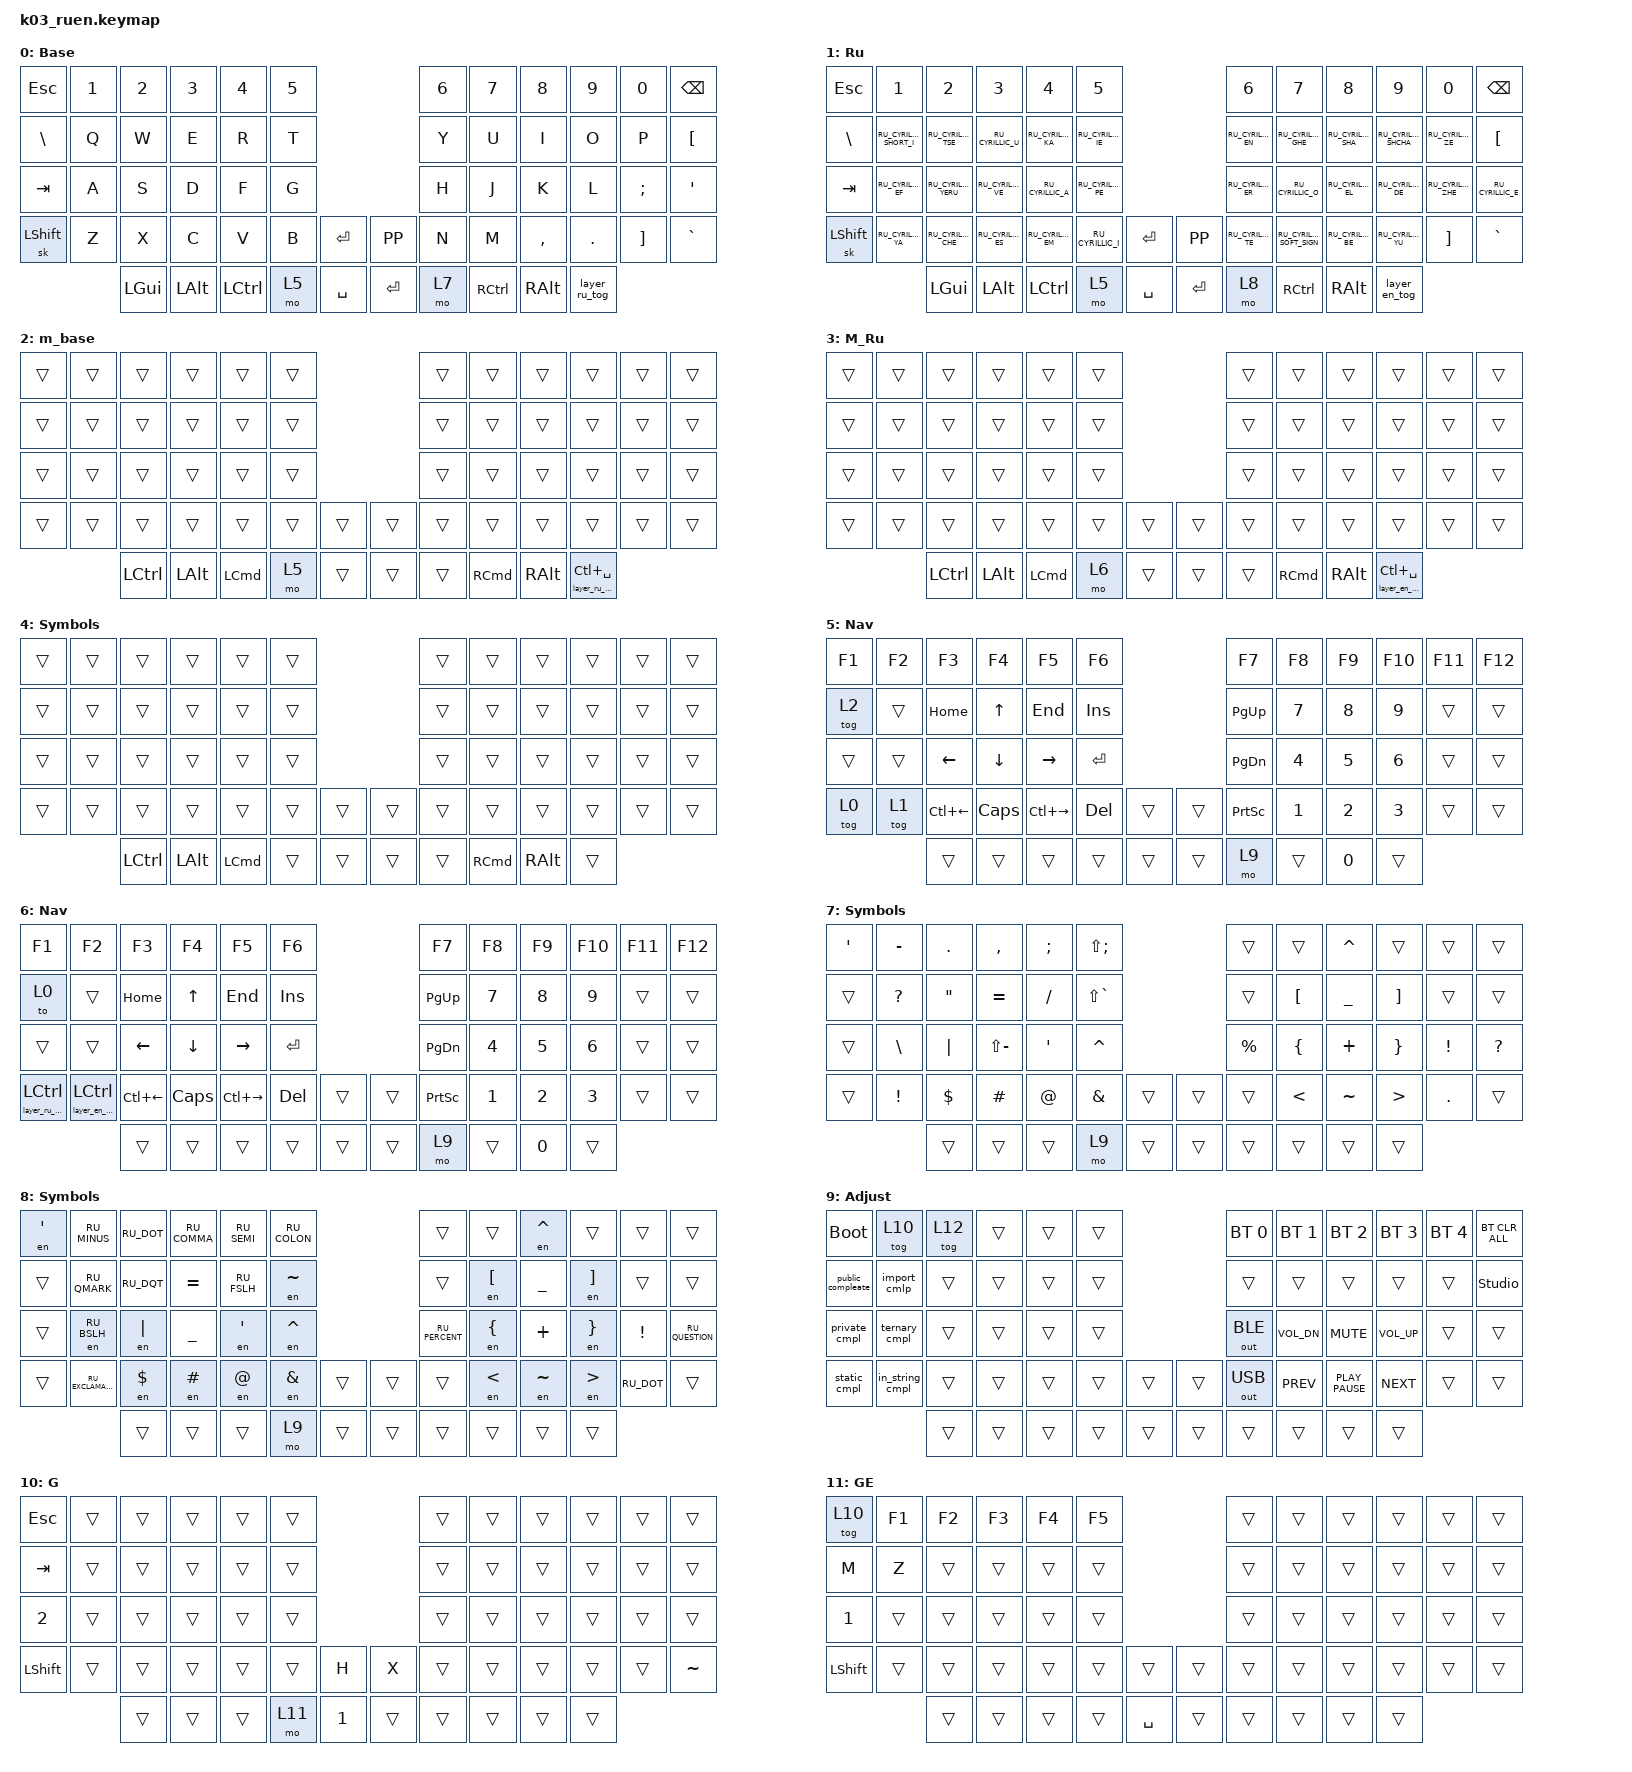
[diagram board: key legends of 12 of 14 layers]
#include "keys_ru.h"
#include <behaviors.dtsi>
#include <dt-bindings/zmk/bt.h>
#include <dt-bindings/zmk/keys.h>
#include <dt-bindings/zmk/outputs.h>

/ {
    behaviors {
        enc_vol: enc_vol {
            compatible = "zmk,behavior-sensor-rotate";
            label = "ENC_VOL";
            #sensor-binding-cells = <0>;
            bindings = <&kp C_VOL_UP>, <&kp C_VOL_DN>;

            tap-ms = <0>;
        };

        enc_up_down: enc_up_down {
            compatible = "zmk,behavior-sensor-rotate";
            label = "ENC_UP_DOWN";
            #sensor-binding-cells = <0>;
            bindings = <&kp UP>, <&kp DOWN>;

            tap-ms = <0>;
        };

        enc_left_right: enc_left_right {
            compatible = "zmk,behavior-sensor-rotate";
            label = "ENC_LEFT_RIGHT";
            #sensor-binding-cells = <0>;
            bindings = <&kp RIGHT>, <&kp LEFT>;

            tap-ms = <0>;
        };

        switch_window: switch_window {
            compatible = "zmk,behavior-sensor-rotate";
            label = "SWITCH_WINDOW";
            #sensor-binding-cells = <0>;
            bindings = <&kp LA(TAB)>, <&kp LS(LA(TAB))>;
        };

        switch_tab: switch_tab {
            compatible = "zmk,behavior-sensor-rotate";
            label = "SWITCH_TAB";
            #sensor-binding-cells = <0>;
            bindings = <&kp LC(TAB)>, <&kp LC(LS(TAB))>;
        };

        game_g_h: game_g_h {
            compatible = "zmk,behavior-sensor-rotate";
            label = "GAME_G_H";
            #sensor-binding-cells = <0>;
            bindings = <&kp G>, <&kp H>;
        };

        game_e_x: game_e_x {
            compatible = "zmk,behavior-sensor-rotate";
            label = "GAME_E_X";
            #sensor-binding-cells = <0>;
            bindings = <&kp E>, <&kp X>;
        };

        mac_switch_window: mac_switch_window {
            compatible = "zmk,behavior-sensor-rotate";
            label = "MAC_SWITCH_WINDOW";
            #sensor-binding-cells = <0>;
            bindings = <&kp LG(TAB)>, <&kp LG(LS(TAB))>;
        };

        enc_tabbing: enc_tabbing {
            compatible = "zmk,behavior-sensor-rotate";
            label = "ENC_TABBING";
            #sensor-binding-cells = <0>;
            bindings = <&kp TAB>, <&kp LS(TAB)>;
        };

        shift_tap_danse: shift_tap_danse {
            compatible = "zmk,behavior-tap-dance";
            label = "SHIFT_TAP_DANSE";
            #binding-cells = <0>;
            bindings = <&sk LSHFT>, <&kp LEFT_SHIFT>;
        };

        rotate_with_param: rotate_with_param {
            compatible = "zmk,behavior-sensor-rotate-var";
            label = "ROTATE_WITH_PARAM";
            #sensor-binding-cells = <2>;
            bindings = <&delayed_macro>, <&delayed_macro>;
        };
    };

    combos {
        compatible = "zmk,combos";

        cmben {
            bindings = <&layer_en>;
            key-positions = <12 13>;
            layers = <1>;
        };

        cmbru {
            bindings = <&layer_ru>;
            key-positions = <12 13>;
            layers = <0>;
        };

        dot_slash {
            bindings = <&dot_slash>;
            key-positions = <2 3>;
            layers = <1>;
        };

        dot_slash_en {
            bindings = <&dot_slash_en>;
            key-positions = <2 3>;
            layers = <0>;
        };
    };

    macros {
        to_ru: to_ru {
            compatible = "zmk,behavior-macro";
            #binding-cells = <0>;
            bindings = <&kp LS(LC(N2))>;
            label = "TO_RU";
            wait-ms = <0>;
            tap-ms = <30>;
        };

        to_en: to_en {
            compatible = "zmk,behavior-macro";
            #binding-cells = <0>;
            bindings = <&kp LS(LC(N1))>;
            label = "TO_EN";
            wait-ms = <0>;
            tap-ms = <30>;
        };

        layer_en: layer_en {
            compatible = "zmk,behavior-macro";
            #binding-cells = <0>;
            bindings = <&to 0 &to_en>;
            label = "LAYER_EN";
            wait-ms = <0>;
            tap-ms = <30>;
        };

        layer_ru: layer_ru {
            compatible = "zmk,behavior-macro";
            #binding-cells = <0>;
            bindings = <&to 1 &to_ru>;
            label = "LAYER_RU";
            tap-ms = <30>;
            wait-ms = <0>;
        };

        en: en {
            compatible = "zmk,behavior-macro-one-param";
            #binding-cells = <1>;
            bindings =
                <&to_en>,
                <&macro_press>,
                <&macro_param_1to1 &kp MACRO_PLACEHOLDER>,
                <&macro_pause_for_release>,
                <&macro_release>,
                <&macro_param_1to1 &kp MACRO_PLACEHOLDER>,
                <&macro_tap>,
                <&to_ru>;

            label = "EN";
            wait-ms = <0>;
            tap-ms = <30>;
        };

        change_lang: change_lang {
            compatible = "zmk,behavior-macro";
            #binding-cells = <0>;
            bindings = <&kp LG(SPACE)>;
            label = "CHANGE_LANG";
        };

        dot_slash: dot_slash {
            compatible = "zmk,behavior-macro";
            #binding-cells = <0>;
            bindings = <&kp RU_DOT &kp RU_SLASH>;
            label = "DOT_SLASH";
        };

        public_compleate: public_compleate {
            compatible = "zmk,behavior-macro";
            #binding-cells = <0>;
            bindings = <&kp P &kp U &kp B &kp L &kp I &kp C &kp SPACE>;
            label = "PUBLIC_COMPLEATE";
        };

        private_cmpl: private_cmpl {
            compatible = "zmk,behavior-macro";
            #binding-cells = <0>;
            bindings = <&kp P &kp R &kp I &kp V &kp A &kp T &kp E &kp SPACE>;
            label = "PRIVATE_CMPL";
        };

        static_cmpl: static_cmpl {
            compatible = "zmk,behavior-macro";
            #binding-cells = <0>;
            bindings = <&kp S &kp T &kp A &kp T &kp I &kp C &kp SPACE>;
            label = "STATIC_CMPL";
        };

        import_cmlp: import_cmlp {
            compatible = "zmk,behavior-macro";
            #binding-cells = <0>;
            bindings = <&kp I &kp M &kp P &kp O &kp R &kp T &kp SPACE>;
            label = "IMPORT_CMLP";
        };

        ternary_cmpl: ternary_cmpl {
            compatible = "zmk,behavior-macro";
            #binding-cells = <0>;
            bindings = <&kp QMARK &kp SPACE &kp SPACE &kp COLON &kp SPACE &kp LEFT &kp LEFT &kp LEFT>;
            label = "TERNARY_CMPL";
        };

        in_string_cmpl: in_string_cmpl {
            compatible = "zmk,behavior-macro";
            #binding-cells = <0>;
            bindings = <&kp BSLH &kp LPAR &kp RPAR &kp LEFT>;
            label = "IN_STRING_CMPL";
        };

        change_lang_mac: change_lang_mac {
            compatible = "zmk,behavior-macro";
            #binding-cells = <0>;
            bindings = <&kp LC(SPACE)>;
            label = "CHANGE_LANG_MAC";
        };

        layer_en_tog: layer_en_tog {
            compatible = "zmk,behavior-macro";
            #binding-cells = <0>;
            bindings = <&to 0 &change_lang>;
            label = "LAYER_EN_TOG";
            wait-ms = <0>;
            tap-ms = <30>;
        };

        layer_ru_tog: layer_ru_tog {
            compatible = "zmk,behavior-macro";
            #binding-cells = <0>;
            bindings = <&to 1 &change_lang>;
            label = "LAYER_RU_TOG";
            wait-ms = <0>;
            tap-ms = <30>;
        };

        layer_ru_mac_tog: layer_ru_mac_tog {
            compatible = "zmk,behavior-macro-one-param";
            #binding-cells = <1>;
            bindings = <&to 1 &tog 3 &macro_param_1to1 &kp MACRO_PLACEHOLDER>;
            label = "LAYER_RU_MAC_TOG";
        };

        layer_en_mac_tog: layer_en_mac_tog {
            compatible = "zmk,behavior-macro-one-param";
            #binding-cells = <1>;
            bindings = <&to 0 &tog 2 &macro_param_1to1 &kp MACRO_PLACEHOLDER>;
            label = "LAYER_EN_MAC_TOG";
        };

        dot_slash_en: dot_slash_en {
            compatible = "zmk,behavior-macro";
            #binding-cells = <0>;
            bindings = <&to_ru &dot_slash &to_en>;
            label = "DOT_SLASH_EN";
        };

        delayed_macro: delayed_macro {
            compatible = "zmk,behavior-macro-one-param";
            #binding-cells = <1>;
            bindings =
                <&macro_pause_for_release>,
                <&macro_tap>,
                <&macro_tap_time 1>,
                <&macro_param_1to1 &kp MACRO_PLACEHOLDER>;

            label = "DELAYED_MACRO";
        };
    };

    keymap {
        compatible = "zmk,keymap";

        en {
            bindings = <
&kp ESC         &kp N1  &kp N2    &kp N3    &kp N4     &kp N5                          &kp N6  &kp N7     &kp N8     &kp N9         &kp N0             &kp BSPC
&kp BACKSLASH   &kp Q   &kp W     &kp E     &kp R      &kp T                           &kp Y   &kp U      &kp I      &kp O          &kp P              &kp LEFT_BRACKET
&kp TAB         &kp A   &kp S     &kp D     &kp F      &kp G                           &kp H   &kp J      &kp K      &kp L          &kp SEMI           &kp SQT
&sk LEFT_SHIFT  &kp Z   &kp X     &kp C     &kp V      &kp B   &kp ENTER    &kp K_PP   &kp N   &kp M      &kp COMMA  &kp DOT        &kp RIGHT_BRACKET  &kp GRAVE
                        &kp LGUI  &kp LALT  &kp LCTRL  &mo 5   &kp SPACE    &kp ENTER  &mo 7   &kp RCTRL  &kp RALT   &layer_ru_tog
            >;

            display-name = "Base";
            sensor-bindings =
                <&rotate_with_param UP DOWN>,
                <&rotate_with_param RIGHT_ARROW LEFT_ARROW>;
        };

        ru {
            display-name = "Ru";
            bindings = <
&kp ESC        &kp N1                   &kp N2                &kp N3              &kp N4              &kp N5                                      &kp N6              &kp N7                     &kp N8               &kp N9                 &kp N0               &kp BSPC
&kp BACKSLASH  &kp RU_CYRILLIC_SHORT_I  &kp RU_CYRILLIC_TSE   &kp RU_CYRILLIC_U   &kp RU_CYRILLIC_KA  &kp RU_CYRILLIC_IE                          &kp RU_CYRILLIC_EN  &kp RU_CYRILLIC_GHE        &kp RU_CYRILLIC_SHA  &kp RU_CYRILLIC_SHCHA  &kp RU_CYRILLIC_ZE   &kp LEFT_BRACKET
&kp TAB        &kp RU_CYRILLIC_EF       &kp RU_CYRILLIC_YERU  &kp RU_CYRILLIC_VE  &kp RU_CYRILLIC_A   &kp RU_CYRILLIC_PE                          &kp RU_CYRILLIC_ER  &kp RU_CYRILLIC_O          &kp RU_CYRILLIC_EL   &kp RU_CYRILLIC_DE     &kp RU_CYRILLIC_ZHE  &kp RU_CYRILLIC_E
&sk LSHFT      &kp RU_CYRILLIC_YA       &kp RU_CYRILLIC_CHE   &kp RU_CYRILLIC_ES  &kp RU_CYRILLIC_EM  &kp RU_CYRILLIC_I   &kp ENTER    &kp K_PP   &kp RU_CYRILLIC_TE  &kp RU_CYRILLIC_SOFT_SIGN  &kp RU_CYRILLIC_BE   &kp RU_CYRILLIC_YU     &kp RIGHT_BRACKET    &kp GRAVE
                                        &kp LGUI              &kp LALT            &kp LCTRL           &mo 5               &kp SPACE    &kp ENTER  &mo 8               &kp RCTRL                  &kp RALT             &layer_en_tog
            >;

            sensor-bindings =
                <&rotate_with_param UP DOWN>,
                <&rotate_with_param RIGHT_ARROW LEFT_ARROW>;
        };

        mac_en {
            bindings = <
&trans  &trans  &trans     &trans        &trans    &trans                    &trans  &trans    &trans    &trans                       &trans  &trans
&trans  &trans  &trans     &trans        &trans    &trans                    &trans  &trans    &trans    &trans                       &trans  &trans
&trans  &trans  &trans     &trans        &trans    &trans                    &trans  &trans    &trans    &trans                       &trans  &trans
&trans  &trans  &trans     &trans        &trans    &trans  &trans    &trans  &trans  &trans    &trans    &trans                       &trans  &trans
                &kp LCTRL  &kp LEFT_ALT  &kp LCMD  &mo 5   &trans    &trans  &trans  &kp RCMD  &kp RALT  &layer_ru_mac_tog LC(SPACE)
            >;

            sensor-bindings =
                <&rotate_with_param UP DOWN_ARROW>,
                <&rotate_with_param RIGHT_ARROW LEFT_ARROW>;

            label = "m_base";
        };

        mac_ru {
            bindings = <
&trans  &trans  &trans     &trans        &trans    &trans                    &trans  &trans    &trans    &trans                       &trans  &trans
&trans  &trans  &trans     &trans        &trans    &trans                    &trans  &trans    &trans    &trans                       &trans  &trans
&trans  &trans  &trans     &trans        &trans    &trans                    &trans  &trans    &trans    &trans                       &trans  &trans
&trans  &trans  &trans     &trans        &trans    &trans  &trans    &trans  &trans  &trans    &trans    &trans                       &trans  &trans
                &kp LCTRL  &kp LEFT_ALT  &kp LCMD  &mo 6   &trans    &trans  &trans  &kp RCMD  &kp RALT  &layer_en_mac_tog LC(SPACE)
            >;

            sensor-bindings =
                <&rotate_with_param UP DOWN_ARROW>,
                <&rotate_with_param RIGHT_ARROW LEFT_ARROW>;

            label = "M_Ru";
        };

        mac_sym {
            bindings = <
&trans  &trans  &trans     &trans        &trans    &trans                    &trans  &trans    &trans    &trans  &trans  &trans
&trans  &trans  &trans     &trans        &trans    &trans                    &trans  &trans    &trans    &trans  &trans  &trans
&trans  &trans  &trans     &trans        &trans    &trans                    &trans  &trans    &trans    &trans  &trans  &trans
&trans  &trans  &trans     &trans        &trans    &trans  &trans    &trans  &trans  &trans    &trans    &trans  &trans  &trans
                &kp LCTRL  &kp LEFT_ALT  &kp LCMD  &trans  &trans    &trans  &trans  &kp RCMD  &kp RALT  &trans
            >;

            label = "Symbols";
            sensor-bindings =
                <&inc_dec_kp LG(TAB) LA(LS(TAB))>,
                <&rotate_with_param LC(TAB) LC(LS(TAB))>;
        };

        nav {
            bindings = <
&kp F1  &kp F2  &kp F3        &kp F4    &kp F5         &kp F6                     &kp F7           &kp F8  &kp F9  &kp F10  &kp F11  &kp F12
&tog 2  &trans  &kp HOME      &kp UP    &kp END        &kp INS                    &kp PG_UP        &kp N7  &kp N8  &kp N9   &trans   &trans
&trans  &trans  &kp LEFT      &kp DOWN  &kp RIGHT      &kp RET                    &kp PG_DN        &kp N4  &kp N5  &kp N6   &trans   &trans
&tog 0  &tog 1  &kp LC(LEFT)  &kp CAPS  &kp LC(RIGHT)  &kp DEL  &trans    &trans  &kp PRINTSCREEN  &kp N1  &kp N2  &kp N3   &trans   &trans
                &trans        &trans    &trans         &trans   &trans    &trans  &mo 9            &trans  &kp N0  &trans
            >;

            display-name = "Nav";
            sensor-bindings = <&enc_vol>, <&rotate_with_param TAB LS(TAB)>;
        };

        nav_mac {
            display-name = "Nav";
            bindings = <
&kp F1                   &kp F2                   &kp F3        &kp F4    &kp F5         &kp F6                     &kp F7           &kp F8  &kp F9  &kp F10  &kp F11  &kp F12
&to 0                    &trans                   &kp HOME      &kp UP    &kp END        &kp INS                    &kp PG_UP        &kp N7  &kp N8  &kp N9   &trans   &trans
&trans                   &trans                   &kp LEFT      &kp DOWN  &kp RIGHT      &kp RET                    &kp PG_DN        &kp N4  &kp N5  &kp N6   &trans   &trans
&layer_ru_mac_tog LCTRL  &layer_en_mac_tog LCTRL  &kp LC(LEFT)  &kp CAPS  &kp LC(RIGHT)  &kp DEL  &trans    &trans  &kp PRINTSCREEN  &kp N1  &kp N2  &kp N3   &trans   &trans
                                                  &trans        &trans    &trans         &trans   &trans    &trans  &mo 9            &trans  &kp N0  &trans
            >;

            sensor-bindings = <&enc_vol>, <&rotate_with_param TAB LS(TAB)>;

            label = "Nav";
        };

        sym_en {
            bindings = <
&kp APOS  &kp MINUS  &kp DOT     &kp COMMA      &kp SEMI     &kp LS(SEMI)                     &trans     &trans         &kp CARET  &trans            &trans    &trans
&trans    &kp QMARK  &kp DQT     &kp EQUAL      &kp FSLH     &kp LS(GRAVE)                    &trans     &kp LBKT       &kp UNDER  &kp RBKT          &trans    &trans
&trans    &kp BSLH   &kp PIPE    &kp LS(MINUS)  &kp APOS     &kp CARET                        &kp PRCNT  &kp LBRC       &kp PLUS   &kp RBRC          &kp EXCL  &kp QUESTION
&trans    &kp EXCL   &kp DOLLAR  &kp HASH       &kp AT_SIGN  &kp AMPERSAND  &trans    &trans  &trans     &kp LESS_THAN  &kp TILDE  &kp GREATER_THAN  &kp DOT   &trans
                     &trans      &trans         &trans       &mo 9          &trans    &trans  &trans     &trans         &trans     &trans
            >;

            display-name = "Symbols";
            sensor-bindings =
                <&rotate_with_param LA(TAB) LS(LA(TAB))>,
                <&rotate_with_param LC(TAB) LC(LS(TAB))>;
        };

        sym_ru {
            display-name = "Symbols";
            bindings = <
&en APOS  &kp RU_MINUS        &kp RU_DOT  &kp RU_COMMA  &kp RU_SEMI  &kp RU_COLON                     &trans          &trans         &en CARET  &trans            &trans      &trans
&trans    &kp RU_QMARK        &kp RU_DQT  &kp EQUAL     &kp RU_FSLH  &en TILDE                        &trans          &en LBKT       &kp UNDER  &en RBKT          &trans      &trans
&trans    &en RU_BSLH         &en PIPE    &kp UNDER     &en APOS     &en CARET                        &kp RU_PERCENT  &en LBRC       &kp PLUS   &en RBRC          &kp EXCL    &kp RU_QUESTION
&trans    &kp RU_EXCLAMATION  &en DOLLAR  &en HASH      &en AT_SIGN  &en AMPERSAND  &trans    &trans  &trans          &en LESS_THAN  &en TILDE  &en GREATER_THAN  &kp RU_DOT  &trans
                              &trans      &trans        &trans       &mo 9          &trans    &trans  &trans          &trans         &trans     &trans
            >;

            sensor-bindings =
                <&rotate_with_param LA(TAB) LS(LA(TAB))>,
                <&rotate_with_param LC(TAB) LS(LC(TAB))>;
        };

        adj {
            bindings = <
&bootloader        &tog 10          &tog 12  &trans  &trans  &trans                    &bt BT_SEL 0  &bt BT_SEL 1  &bt BT_SEL 2      &bt BT_SEL 3  &bt BT_SEL 4  &bt BT_CLR_ALL
&public_compleate  &import_cmlp     &trans   &trans  &trans  &trans                    &trans        &trans        &trans            &trans        &trans        &studio_unlock
&private_cmpl      &ternary_cmpl    &trans   &trans  &trans  &trans                    &out OUT_BLE  &kp C_VOL_DN  &kp K_MUTE        &kp C_VOL_UP  &trans        &trans
&static_cmpl       &in_string_cmpl  &trans   &trans  &trans  &trans  &trans    &trans  &out OUT_USB  &kp K_PREV    &kp K_PLAY_PAUSE  &kp K_NEXT    &trans        &trans
                                    &trans   &trans  &trans  &trans  &trans    &trans  &trans        &trans        &trans            &trans
            >;

            display-name = "Adjust";
        };

        games {
            bindings = <
&kp ESC       &trans  &trans  &trans  &trans  &trans                    &trans  &trans  &trans  &trans  &trans  &trans
&kp TAB       &trans  &trans  &trans  &trans  &trans                    &trans  &trans  &trans  &trans  &trans  &trans
&kp NUMBER_2  &trans  &trans  &trans  &trans  &trans                    &trans  &trans  &trans  &trans  &trans  &trans
&kp LSHIFT    &trans  &trans  &trans  &trans  &trans  &kp H     &kp X   &trans  &trans  &trans  &trans  &trans  &kp TILDE
                      &trans  &trans  &trans  &mo 11  &kp N1    &trans  &trans  &trans  &trans  &trans
            >;

            label = "G";
            sensor-bindings =
                <&rotate_with_param G H>,
                <&rotate_with_param E X>;
        };

        games_extension {
            bindings = <
&tog 10     &kp F1  &kp F2  &kp F3  &kp F4  &kp F5                       &trans  &trans  &trans  &trans  &trans  &trans
&kp M       &kp Z   &trans  &trans  &trans  &trans                       &trans  &trans  &trans  &trans  &trans  &trans
&kp N1      &trans  &trans  &trans  &trans  &trans                       &trans  &trans  &trans  &trans  &trans  &trans
&kp LSHIFT  &trans  &trans  &trans  &trans  &trans  &trans       &trans  &trans  &trans  &trans  &trans  &trans  &trans
                    &trans  &trans  &trans  &trans  &kp SPACE    &trans  &trans  &trans  &trans  &trans
            >;

            label = "GE";
        };

        sifu {
            bindings = <
&kp ESC       &kp LCTRL  &kp LC(W)  &kp LC(S)  &trans  &trans                       &trans  &trans  &trans  &trans  &trans  &trans
&kp TAB       &trans     &trans     &trans     &trans  &trans                       &trans  &trans  &trans  &trans  &trans  &trans
&kp NUMBER_2  &trans     &trans     &trans     &trans  &trans                       &trans  &trans  &trans  &trans  &trans  &trans
&kp LSHIFT    &trans     &trans     &trans     &trans  &trans  &kp H     &kp X      &trans  &trans  &trans  &trans  &trans  &kp TILDE
                         &kp LCTRL  &trans     &trans  &mo 13  &kp N1    &kp ENTER  &trans  &trans  &trans  &trans
            >;

            label = "sfu";
            sensor-bindings =
                <&rotate_with_param G H>,
                <&rotate_with_param E X>;
        };

        sifu_extension {
            bindings = <
&tog 12     &kp F1     &kp F2        &kp F3        &kp F4     &kp F5                       &trans  &trans  &trans  &trans  &trans  &trans
&kp M       &kp N1     &kp NUMBER_2  &kp NUMBER_3  &trans     &trans                       &trans  &trans  &trans  &trans  &trans  &trans
&kp N1      &kp LC(A)  &kp LC(S)     &kp LC(D)     &kp LCTRL  &trans                       &trans  &trans  &trans  &trans  &trans  &trans
&kp LSHIFT  &trans     &trans        &trans        &trans     &trans  &trans       &trans  &trans  &trans  &trans  &trans  &trans  &trans
                       &trans        &trans        &trans     &trans  &kp SPACE    &trans  &trans  &trans  &trans  &trans
            >;

            label = "sfu_e";
        };
    };
};
